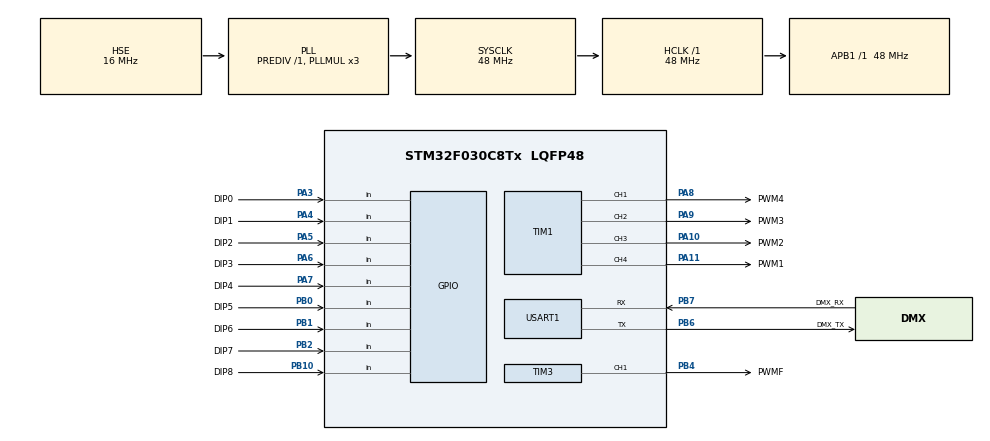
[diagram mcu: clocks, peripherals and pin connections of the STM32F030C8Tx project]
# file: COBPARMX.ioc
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Mcu.Family=STM32F0
Mcu.Name=STM32F030C8Tx
Mcu.Package=LQFP48
PA10.GPIO_Label=PWM2
PA10.Signal=S_TIM1_CH3
PA11.GPIO_Label=PWM1
PA11.Signal=S_TIM1_CH4
PA13.Mode=Serial_Wire
PA13.Signal=SYS_SWDIO
PA14.Mode=Serial_Wire
PA14.Signal=SYS_SWCLK
PA3.GPIO_Label=DIP0
PA3.GPIO_Mode=GPIO_MODE_INPUT
PA3.GPIO_PuPd=GPIO_PULLUP
PA3.Signal=GPIO_Input
PA4.GPIO_Label=DIP1
PA4.GPIO_Mode=GPIO_MODE_INPUT
PA4.GPIO_PuPd=GPIO_PULLUP
PA4.Signal=GPIO_Input
PA5.GPIO_Label=DIP2
PA5.GPIO_Mode=GPIO_MODE_INPUT
PA5.GPIO_PuPd=GPIO_PULLUP
PA5.Signal=GPIO_Input
PA6.GPIO_Label=DIP3
PA6.GPIO_Mode=GPIO_MODE_INPUT
PA6.GPIO_PuPd=GPIO_PULLUP
PA6.Signal=GPIO_Input
PA7.GPIO_Label=DIP4
PA7.GPIO_Mode=GPIO_MODE_INPUT
PA7.GPIO_PuPd=GPIO_PULLUP
PA7.Signal=GPIO_Input
PA8.GPIO_Label=PWM4
PA8.Signal=S_TIM1_CH1
PA9.GPIO_Label=PWM3
PA9.Signal=S_TIM1_CH2
PB0.GPIO_Label=DIP5
PB0.GPIO_Mode=GPIO_MODE_INPUT
PB0.GPIO_PuPd=GPIO_PULLUP
PB0.Signal=GPIO_Input
PB1.GPIO_Label=DIP6
PB1.GPIO_Mode=GPIO_MODE_INPUT
PB1.GPIO_PuPd=GPIO_PULLUP
PB1.Signal=GPIO_Input
PB10.GPIO_Label=DIP8
PB10.GPIO_Mode=GPIO_MODE_INPUT
PB10.GPIO_PuPd=GPIO_PULLUP
PB10.Signal=GPIO_Input
PB2.GPIO_Label=DIP7
PB2.GPIO_Mode=GPIO_MODE_INPUT
PB2.GPIO_PuPd=GPIO_PULLUP
PB2.Signal=GPIO_Input
PB4.GPIO_Label=PWMF
PB4.Signal=S_TIM3_CH1
PB6.GPIO_Label=DMX_TX
PB6.Mode=Asynchronous
PB6.Signal=USART1_TX
PB7.GPIO_Label=DMX_RX
PB7.Mode=Asynchronous
PB7.Signal=USART1_RX
PF0-OSC_IN.Mode=HSE-External-Oscillator
PF0-OSC_IN.Signal=RCC_OSC_IN
PF1-OSC_OUT.Mode=HSE-External-Oscillator
PF1-OSC_OUT.Signal=RCC_OSC_OUT
ProjectManager.HeapSize=0x200
ProjectManager.StackSize=0x400
ProjectManager.TargetToolchain=Makefile
RCC.AHBFreq_Value=48000000
RCC.APB1Freq_Value=48000000
RCC.APB1TimFreq_Value=48000000
RCC.HCLKFreq_Value=48000000
RCC.HSE_VALUE=16000000
RCC.HSIState=RCC_HSI_ON
RCC.PLLMUL=RCC_PLL_MUL3
RCC.PLLSourceVirtual=RCC_PLLSOURCE_HSE
RCC.SYSCLKFreq_VALUE=48000000
RCC.SYSCLKSource=RCC_SYSCLKSOURCE_PLLCLK
SH.S_TIM1_CH1.0=TIM1_CH1,PWM Generation1 CH1
SH.S_TIM1_CH2.0=TIM1_CH2,PWM Generation2 CH2
SH.S_TIM1_CH3.0=TIM1_CH3,PWM Generation3 CH3
SH.S_TIM1_CH4.0=TIM1_CH4,PWM Generation4 CH4
SH.S_TIM3_CH1.0=TIM3_CH1,Output Compare1 CH1
TIM1.Channel-PWM\ Generation1\ CH1=TIM_CHANNEL_1
TIM1.Channel-PWM\ Generation2\ CH2=TIM_CHANNEL_2
TIM1.Channel-PWM\ Generation3\ CH3=TIM_CHANNEL_3
TIM1.Channel-PWM\ Generation4\ CH4=TIM_CHANNEL_4
TIM3.Channel-Output\ Compare1\ CH1=TIM_CHANNEL_1
USART1.VirtualMode-Asynchronous=VM_ASYNC
VP_TIM1_VS_ClockSourceINT.Mode=Internal
VP_TIM3_VS_ClockSourceINT.Mode=Internal
board=custom

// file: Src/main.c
/* USER CODE BEGIN Header */
/**
  ******************************************************************************
  * @file           : main.c
  * @brief          : Main program body
  ******************************************************************************
  * @attention
  *
  * <h2><center>&copy; Copyright (c) 2019 STMicroelectronics.
  * All rights reserved.</center></h2>
  *
  * This software component is licensed by ST under BSD 3-Clause license,
  * the "License"; You may not use this file except in compliance with the
  * License. You may obtain a copy of the License at:
  *                        opensource.org/licenses/BSD-3-Clause
  *
  ******************************************************************************
  */
/* USER CODE END Header */

#include "main.h"

TIM_HandleTypeDef htim1;
TIM_HandleTypeDef htim3;

UART_HandleTypeDef huart1;

DMA_HandleTypeDef hdma_usart1_rx;

IWDG_HandleTypeDef iwdg;

void SystemClock_Config(void);
static void MX_GPIO_Init(void);
static void MX_DMA_Init(void);
static void MX_TIM1_Init(void);
static void MX_TIM3_Init(void);
static void MX_USART1_UART_Init(void);

uint8_t dmx_buffer[514];
uint8_t dmx_buffer_shadow[512];
uint16_t pwm_data[3];

uint16_t fan_buf = 0;
const float alpha = 0.001;

const float max_duty[3] = {0.25, 0.5, 0.45};
const uint16_t gamma_map[] = {0,1,1,1,2,2,3,4,5,7,9,11,14,17,20,25,29,34,40,47,54,61,70,79,89,99,111,123,136,150,165,180,197,215,233,253,274,296,318,342,367,394,421,450,479,511,543,576,611,648,685,724,765,807,850,895,941,989,1038,1089,1141,1195,1251,1308,1367,1428,1490,1554,1620,1687,1757,1828,1901,1976,2052,2131,2211,2294,2378,2464,2553,2643,2735,2830,2926,3025,3125,3228,3333,3440,3549,3661,3775,3891,4009,4129,4252,4377,4505,4635,4767,4902,5039,5178,5320,5465,5612,5761,5913,6068,6225,6384,6547,6712,6879,7050,7223,7398,7577,7758,7942,8128,8318,8510,8705,8903,9104,9308,9515,9724,9937,10152,10371,10592,10817,11044,11275,11508,11745,11985,12228,12474,12723,12976,13231,13490,13752,14018,14286,14558,14833,15112,15394,15679,15968,16260,16555,16854,17156,17462,17771,18084,18400,18720,19043,19370,19701,20035,20372,20714,21059,21407,21760,22116,22476,22839,23206,23577,23952,24331,24714,25100,25490,25884,26282,26684,27090,27500,27913,28331,28753,29178,29608,30042,30480,30922,31368,31818,32272,32731,33193,33660,34131,34606,35086,35569,36057,36550,37046,37547,38052,38562,39076,39594,40117,40644,41175,41711,42252,42796,43346,43900,44458,45021,45589,46161,46738,47319,47905,48496,49091,49691,50296,50905,51519,52138,52761,53390,54023,54661,55304,55951,56604,57261,57923,58590,59262,59939,60621,61308,62000,62697,63399,64106,64818,65535};

uint16_t fan_speed(uint16_t values[3]){
  // calculate avg brightness among colors
  uint16_t avg_val = ((values[0]/max_duty[0]) + (values[1]/max_duty[1]) + (values[2]/max_duty[2])) / (3*16);
  fan_buf = (alpha * avg_val) + (1.0 - alpha) * fan_buf;
  return fan_buf;
}

void HAL_UART_RxCpltCallback(UART_HandleTypeDef *huart)
{
  // nothing
}

uint16_t getAddress(){
  uint16_t ret = 0;
  /*uint8_t map = {
    HAL_GPIO_ReadPin(GPIOA, DIP0_Pin),
    HAL_GPIO_ReadPin(GPIOA, DIP1_Pin),
    HAL_GPIO_ReadPin(GPIOA, DIP2_Pin),
    HAL_GPIO_ReadPin(GPIOA, DIP3_Pin),
    HAL_GPIO_ReadPin(GPIOA, DIP4_Pin),
    HAL_GPIO_ReadPin(GPIOB, DIP5_Pin),
    HAL_GPIO_ReadPin(GPIOB, DIP6_Pin),
    HAL_GPIO_ReadPin(GPIOB, DIP7_Pin),
    HAL_GPIO_ReadPin(GPIOB, DIP8_Pin),
  };*/

  ret =
    !HAL_GPIO_ReadPin(GPIOA, DIP0_Pin)
  | !HAL_GPIO_ReadPin(GPIOA, DIP1_Pin) << 1
  | !HAL_GPIO_ReadPin(GPIOA, DIP2_Pin) << 2
  | !HAL_GPIO_ReadPin(GPIOA, DIP3_Pin) << 3
  | !HAL_GPIO_ReadPin(GPIOA, DIP4_Pin) << 4
  | !HAL_GPIO_ReadPin(GPIOB, DIP5_Pin) << 5
  | !HAL_GPIO_ReadPin(GPIOB, DIP6_Pin) << 6
  | !HAL_GPIO_ReadPin(GPIOB, DIP7_Pin) << 7
  | !HAL_GPIO_ReadPin(GPIOB, DIP8_Pin) << 8;

  return ret;
}

size_t old_systick = 0;

size_t systick_delta = 0;

size_t reset_counter = 0;

uint32_t speed = 0;

int main(void)
{

  /* MCU Configuration--------------------------------------------------------*/

  /* Reset of all peripherals, Initializes the Flash interface and the Systick. */
  HAL_Init();

  /* Configure the system clock */
  SystemClock_Config();

  /* Initialize all configured peripherals */
  MX_GPIO_Init();
  MX_DMA_Init();
  MX_TIM1_Init();
  MX_TIM3_Init();
  MX_USART1_UART_Init();
  /* USER CODE BEGIN 2 */

  HAL_TIM_Base_Start(&htim1);
  HAL_TIM_PWM_Start(&htim1, TIM_CHANNEL_3); // blue
  HAL_TIM_PWM_Start(&htim1, TIM_CHANNEL_2); // green
  HAL_TIM_PWM_Start(&htim1, TIM_CHANNEL_1); // white
  HAL_TIM_PWM_Start(&htim1, TIM_CHANNEL_4); // red

  HAL_TIM_Base_Start(&htim3);
  HAL_TIM_PWM_Start(&htim3, TIM_CHANNEL_1);
  //__HAL_TIM_SET_COMPARE(&htim3, TIM_CHANNEL_1, 0xFFF);

  // start DMA
  __HAL_UART_ENABLE_IT(&huart1, UART_IT_IDLE);
  HAL_UART_Receive_DMA(&huart1, (uint8_t *)&dmx_buffer, sizeof(dmx_buffer));

  // init watchdog
  // LSI = 40kHz
  iwdg.Instance       = IWDG;
  iwdg.Init.Prescaler = IWDG_PRESCALER_32;
  iwdg.Init.Reload    = 40000/16;
  iwdg.Init.Window    = 0;

  //HAL_IWDG_Init(&iwdg);

  //__HAL_TIM_SET_COMPARE(&htim1, TIM_CHANNEL_3, 100);
  /* USER CODE END 2 */

  /* Infinite loop */
  /* USER CODE BEGIN WHILE */

  old_systick = HAL_GetTick();

  while (1)
  {
    uint32_t errorcode = huart1.ErrorCode;
    size_t curr_systick = HAL_GetTick();
    if(errorcode != 0 && huart1.RxXferSize == 514){
      old_systick = curr_systick;
      // HAL_IWDG_Refresh(&iwdg);

      HAL_UART_DMAStop(&huart1);
      uint16_t address =  getAddress();
      HAL_UART_Receive_DMA(&huart1, (uint8_t *)&dmx_buffer, sizeof(dmx_buffer));
      memcpy(dmx_buffer_shadow, dmx_buffer + 1, sizeof(dmx_buffer_shadow));
      pwm_data[0] = gamma_map[dmx_buffer_shadow[address + 0]] * max_duty[0];
      pwm_data[1] = gamma_map[dmx_buffer_shadow[address + 1]] * max_duty[1];
      pwm_data[2] = gamma_map[dmx_buffer_shadow[address + 2]] * max_duty[2];

      // set fan speed
      speed = fan_speed(pwm_data) + 2000;
      if(speed < 2500){
        speed = 0;
      } else if (speed > 4096) {
        speed = 4096;
      }
      __HAL_TIM_SET_COMPARE(&htim3, TIM_CHANNEL_1, speed);

      __HAL_TIM_SET_COMPARE(&htim1, TIM_CHANNEL_4, pwm_data[0]);
      __HAL_TIM_SET_COMPARE(&htim1, TIM_CHANNEL_2, pwm_data[2]);
      __HAL_TIM_SET_COMPARE(&htim1, TIM_CHANNEL_3, pwm_data[1]);

      huart1.ErrorCode = 0;
      //__HAL_IWDG_RELOAD_COUNTER(&iwdg);
    }else{
      systick_delta = curr_systick - old_systick;
      if(systick_delta > 500){
        NVIC_SystemReset();
      }
    }
  }
}

void SystemClock_Config(void)
{
  RCC_OscInitTypeDef RCC_OscInitStruct = {0};
  RCC_ClkInitTypeDef RCC_ClkInitStruct = {0};
  RCC_PeriphCLKInitTypeDef PeriphClkInit = {0};

  /** Initializes the CPU, AHB and APB busses clocks
  */
  RCC_OscInitStruct.OscillatorType = RCC_OSCILLATORTYPE_HSE;
  RCC_OscInitStruct.HSEState = RCC_HSE_ON;
  RCC_OscInitStruct.PLL.PLLState = RCC_PLL_ON;
  RCC_OscInitStruct.PLL.PLLSource = RCC_PLLSOURCE_HSE;
  RCC_OscInitStruct.PLL.PLLMUL = RCC_PLL_MUL3;
  RCC_OscInitStruct.PLL.PREDIV = RCC_PREDIV_DIV1;
  if (HAL_RCC_OscConfig(&RCC_OscInitStruct) != HAL_OK)
  {
    Error_Handler();
  }
  /** Initializes the CPU, AHB and APB busses clocks
  */
  RCC_ClkInitStruct.ClockType = RCC_CLOCKTYPE_HCLK|RCC_CLOCKTYPE_SYSCLK
                              |RCC_CLOCKTYPE_PCLK1;
  RCC_ClkInitStruct.SYSCLKSource = RCC_SYSCLKSOURCE_PLLCLK;
  RCC_ClkInitStruct.AHBCLKDivider = RCC_SYSCLK_DIV1;
  RCC_ClkInitStruct.APB1CLKDivider = RCC_HCLK_DIV1;

  if (HAL_RCC_ClockConfig(&RCC_ClkInitStruct, FLASH_LATENCY_1) != HAL_OK)
  {
    Error_Handler();
  }
  PeriphClkInit.PeriphClockSelection = RCC_PERIPHCLK_USART1;
  PeriphClkInit.Usart1ClockSelection = RCC_USART1CLKSOURCE_PCLK1;
  if (HAL_RCCEx_PeriphCLKConfig(&PeriphClkInit) != HAL_OK)
  {
    Error_Handler();
  }
}

static void MX_TIM1_Init(void)
{

  TIM_ClockConfigTypeDef sClockSourceConfig = {0};
  TIM_MasterConfigTypeDef sMasterConfig = {0};
  TIM_OC_InitTypeDef sConfigOC = {0};
  TIM_BreakDeadTimeConfigTypeDef sBreakDeadTimeConfig = {0};

  htim1.Instance = TIM1;
  htim1.Init.Prescaler = 0;
  htim1.Init.CounterMode = TIM_COUNTERMODE_UP;
  htim1.Init.Period = 0xFFFF;
  htim1.Init.ClockDivision = TIM_CLOCKDIVISION_DIV1;
  htim1.Init.RepetitionCounter = 0;
  htim1.Init.AutoReloadPreload = TIM_AUTORELOAD_PRELOAD_ENABLE;
  if (HAL_TIM_Base_Init(&htim1) != HAL_OK)
  {
    Error_Handler();
  }
  sClockSourceConfig.ClockSource = TIM_CLOCKSOURCE_INTERNAL;
  if (HAL_TIM_ConfigClockSource(&htim1, &sClockSourceConfig) != HAL_OK)
  {
    Error_Handler();
  }
  if (HAL_TIM_PWM_Init(&htim1) != HAL_OK)
  {
    Error_Handler();
  }
  sMasterConfig.MasterOutputTrigger = TIM_TRGO_RESET;
  sMasterConfig.MasterSlaveMode = TIM_MASTERSLAVEMODE_DISABLE;
  if (HAL_TIMEx_MasterConfigSynchronization(&htim1, &sMasterConfig) != HAL_OK)
  {
    Error_Handler();
  }
  sConfigOC.OCMode = TIM_OCMODE_PWM1;
  sConfigOC.Pulse = 0;
  sConfigOC.OCPolarity = TIM_OCPOLARITY_HIGH;
  sConfigOC.OCNPolarity = TIM_OCNPOLARITY_HIGH;
  sConfigOC.OCFastMode = TIM_OCFAST_DISABLE;
  sConfigOC.OCIdleState = TIM_OCIDLESTATE_RESET;
  sConfigOC.OCNIdleState = TIM_OCNIDLESTATE_RESET;
  if (HAL_TIM_PWM_ConfigChannel(&htim1, &sConfigOC, TIM_CHANNEL_1) != HAL_OK)
  {
    Error_Handler();
  }
  if (HAL_TIM_PWM_ConfigChannel(&htim1, &sConfigOC, TIM_CHANNEL_2) != HAL_OK)
  {
    Error_Handler();
  }
  if (HAL_TIM_PWM_ConfigChannel(&htim1, &sConfigOC, TIM_CHANNEL_3) != HAL_OK)
  {
    Error_Handler();
  }
  if (HAL_TIM_PWM_ConfigChannel(&htim1, &sConfigOC, TIM_CHANNEL_4) != HAL_OK)
  {
    Error_Handler();
  }
  sBreakDeadTimeConfig.OffStateRunMode = TIM_OSSR_DISABLE;
  sBreakDeadTimeConfig.OffStateIDLEMode = TIM_OSSI_DISABLE;
  sBreakDeadTimeConfig.LockLevel = TIM_LOCKLEVEL_OFF;
  sBreakDeadTimeConfig.DeadTime = 0;
  sBreakDeadTimeConfig.BreakState = TIM_BREAK_DISABLE;
  sBreakDeadTimeConfig.BreakPolarity = TIM_BREAKPOLARITY_HIGH;
  sBreakDeadTimeConfig.AutomaticOutput = TIM_AUTOMATICOUTPUT_DISABLE;
  if (HAL_TIMEx_ConfigBreakDeadTime(&htim1, &sBreakDeadTimeConfig) != HAL_OK)
  {
    Error_Handler();
  }
  HAL_TIM_MspPostInit(&htim1);

}

static void MX_TIM3_Init(void)
{

  TIM_ClockConfigTypeDef sClockSourceConfig = {0};
  TIM_MasterConfigTypeDef sMasterConfig = {0};
  TIM_OC_InitTypeDef sConfigOC = {0};

  htim3.Instance = TIM3;
  htim3.Init.Prescaler = 255;
  htim3.Init.CounterMode = TIM_COUNTERMODE_UP;
  htim3.Init.Period = 0xFFF;
  htim3.Init.ClockDivision = TIM_CLOCKDIVISION_DIV4;
  htim3.Init.AutoReloadPreload = TIM_AUTORELOAD_PRELOAD_ENABLE;
  if (HAL_TIM_Base_Init(&htim3) != HAL_OK)
  {
    Error_Handler();
  }
  sClockSourceConfig.ClockSource = TIM_CLOCKSOURCE_INTERNAL;
  if (HAL_TIM_ConfigClockSource(&htim3, &sClockSourceConfig) != HAL_OK)
  {
    Error_Handler();
  }
  if (HAL_TIM_OC_Init(&htim3) != HAL_OK)
  {
    Error_Handler();
  }
  sMasterConfig.MasterOutputTrigger = TIM_TRGO_RESET;
  sMasterConfig.MasterSlaveMode = TIM_MASTERSLAVEMODE_DISABLE;
  if (HAL_TIMEx_MasterConfigSynchronization(&htim3, &sMasterConfig) != HAL_OK)
  {
    Error_Handler();
  }

  sConfigOC.OCMode = TIM_OCMODE_PWM1;
  sConfigOC.Pulse = 0;
  sConfigOC.OCPolarity = TIM_OCPOLARITY_HIGH;
  sConfigOC.OCNPolarity = TIM_OCNPOLARITY_HIGH;
  sConfigOC.OCFastMode = TIM_OCFAST_DISABLE;
  sConfigOC.OCIdleState = TIM_OCIDLESTATE_RESET;
  sConfigOC.OCNIdleState = TIM_OCNIDLESTATE_RESET;
  if (HAL_TIM_PWM_ConfigChannel(&htim3, &sConfigOC, TIM_CHANNEL_1) != HAL_OK)
  {
    Error_Handler();
  }

  HAL_TIM_MspPostInit(&htim3);

}

static void MX_DMA_Init(void)
{
  /* DMA controller clock enable */
  __HAL_RCC_DMA1_CLK_ENABLE();

  /* DMA interrupt init */
  /* DMA1_Channel2_3_IRQn interrupt configuration */
  HAL_NVIC_SetPriority(DMA1_Channel2_3_IRQn, 0, 0);
  HAL_NVIC_EnableIRQ(DMA1_Channel2_3_IRQn);

}

static void MX_USART1_UART_Init(void)
{

  huart1.Instance = USART1;
  huart1.Init.BaudRate = 250000;
  huart1.Init.WordLength = UART_WORDLENGTH_8B;
  huart1.Init.StopBits = UART_STOPBITS_2;
  huart1.Init.Parity = UART_PARITY_NONE;
  huart1.Init.Mode = UART_MODE_RX;
  huart1.Init.HwFlowCtl = UART_HWCONTROL_NONE;
  huart1.Init.OverSampling = UART_OVERSAMPLING_16;
  huart1.Init.OneBitSampling = UART_ONE_BIT_SAMPLE_DISABLE;
  huart1.AdvancedInit.AdvFeatureInit = UART_ADVFEATURE_NO_INIT;
  if (HAL_UART_Init(&huart1) != HAL_OK)
  {
    Error_Handler();
  }

}

static void MX_GPIO_Init(void)
{
  GPIO_InitTypeDef GPIO_InitStruct = {0};

  /* GPIO Ports Clock Enable */
  __HAL_RCC_GPIOF_CLK_ENABLE();
  __HAL_RCC_GPIOA_CLK_ENABLE();
  __HAL_RCC_GPIOB_CLK_ENABLE();

  /*Configure GPIO pins : DIP0_Pin DIP1_Pin DIP2_Pin DIP3_Pin
                           DIP4_Pin */
  GPIO_InitStruct.Pin = DIP0_Pin|DIP1_Pin|DIP2_Pin|DIP3_Pin
                          |DIP4_Pin;
  GPIO_InitStruct.Mode = GPIO_MODE_INPUT;
  GPIO_InitStruct.Pull = GPIO_PULLUP;
  HAL_GPIO_Init(GPIOA, &GPIO_InitStruct);

  /*Configure GPIO pins : DIP5_Pin DIP6_Pin DIP7_Pin DIP8_Pin */
  GPIO_InitStruct.Pin = DIP5_Pin|DIP6_Pin|DIP7_Pin|DIP8_Pin;
  GPIO_InitStruct.Mode = GPIO_MODE_INPUT;
  GPIO_InitStruct.Pull = GPIO_PULLUP;
  HAL_GPIO_Init(GPIOB, &GPIO_InitStruct);
}

void Error_Handler(void)
{
}

/************************ (C) COPYRIGHT STMicroelectronics *****END OF FILE****/
